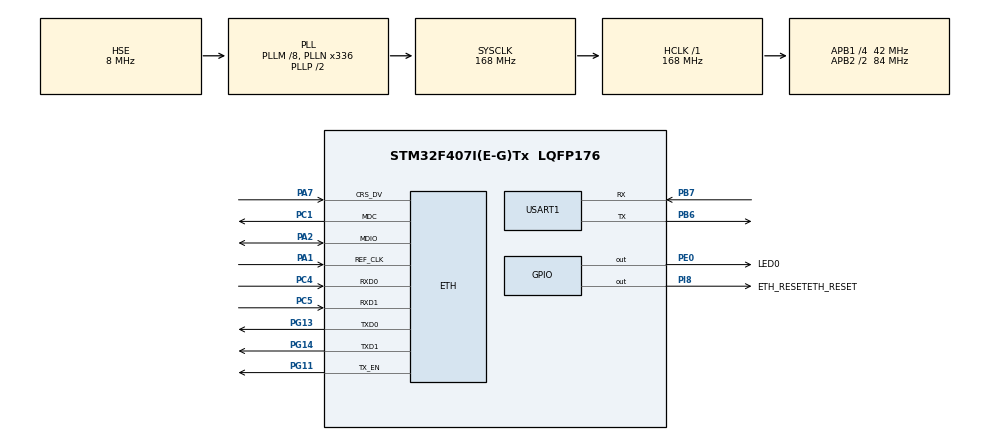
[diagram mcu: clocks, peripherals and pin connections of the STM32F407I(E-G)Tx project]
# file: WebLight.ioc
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ETH.MediaInterface=ETH_MEDIA_INTERFACE_RMII
ETH.PHY_DUPLEX_STATUS=0x2000
ETH.PHY_Name_RMII=userPHY
ETH.PHY_SPEED_STATUS=0x4010
ETH.PHY_SR=0x11
ETH.PhyAddress=0
FREERTOS.Tasks01=defaultTask,0,1024,StartDefaultTask,Default,NULL,Dynamic,NULL,NULL
LWIP.GATEWAY_ADDRESS=010.010.001.001
LWIP.IP_ADDRESS=010.010.001.022
LWIP.LWIP_DHCP=0
LWIP.LWIP_DNS=1
LWIP.LWIP_IGMP=1
LWIP.LWIP_MULTICAST_TX_OPTIONS=1
LWIP.NETMASK_ADDRESS=255.255.255.000
LWIP.Version=v2.0.3_Cube
Mcu.Family=STM32F4
Mcu.Name=STM32F407I(E-G)Tx
Mcu.Package=LQFP176
NVIC.ETH_IRQn=true\:5\:0\:true\:false\:true\:true\:true\:true
NVIC.PriorityGroup=NVIC_PRIORITYGROUP_4
NVIC.TIM1_UP_TIM10_IRQn=true\:0\:0\:false\:false\:true\:false\:false\:true
NVIC.TimeBase=TIM1_UP_TIM10_IRQn
NVIC.TimeBaseIP=TIM1
PA1.Mode=RMII
PA1.Signal=ETH_REF_CLK
PA13.Mode=Serial_Wire
PA13.Signal=SYS_JTMS-SWDIO
PA14.Mode=Serial_Wire
PA14.Signal=SYS_JTCK-SWCLK
PA2.Mode=RMII
PA2.Signal=ETH_MDIO
PA7.Mode=RMII
PA7.Signal=ETH_CRS_DV
PB6.Mode=Asynchronous
PB6.Signal=USART1_TX
PB7.Mode=Asynchronous
PB7.Signal=USART1_RX
PC1.Mode=RMII
PC1.Signal=ETH_MDC
PC4.Mode=RMII
PC4.Signal=ETH_RXD0
PC5.Mode=RMII
PC5.Signal=ETH_RXD1
PE0.GPIO_Label=LED0
PE0.GPIO_Speed=GPIO_SPEED_FREQ_HIGH
PE0.PinState=GPIO_PIN_SET
PE0.Signal=GPIO_Output
PG11.Mode=RMII
PG11.Signal=ETH_TX_EN
PG13.Mode=RMII
PG13.Signal=ETH_TXD0
PG14.Mode=RMII
PG14.Signal=ETH_TXD1
PH0-OSC_IN.Mode=HSE-External-Oscillator
PH0-OSC_IN.Signal=RCC_OSC_IN
PH1-OSC_OUT.Mode=HSE-External-Oscillator
PH1-OSC_OUT.Signal=RCC_OSC_OUT
PI8-\ ANTI\ TAMP2.GPIO_Label=ETH_RESETETH_RESET
PI8-\ ANTI\ TAMP2.GPIO_Speed=GPIO_SPEED_FREQ_VERY_HIGH
PI8-\ ANTI\ TAMP2.PinState=GPIO_PIN_SET
PI8-\ ANTI\ TAMP2.Signal=GPIO_Output
ProjectManager.HeapSize=0x200
ProjectManager.StackSize=0x400
ProjectManager.TargetToolchain=MDK-ARM V5
RCC.48MHZClocksFreq_Value=84000000
RCC.AHBFreq_Value=168000000
RCC.APB1CLKDivider=RCC_HCLK_DIV4
RCC.APB1Freq_Value=42000000
RCC.APB1TimFreq_Value=84000000
RCC.APB2CLKDivider=RCC_HCLK_DIV2
RCC.APB2Freq_Value=84000000
RCC.APB2TimFreq_Value=168000000
RCC.CortexFreq_Value=168000000
RCC.HCLKFreq_Value=168000000
RCC.HSE_VALUE=8000000
RCC.HSI_VALUE=16000000
RCC.LSE_VALUE=32768
RCC.PLLM=8
RCC.PLLN=336
RCC.PLLSourceVirtual=RCC_PLLSOURCE_HSE
RCC.SYSCLKFreq_VALUE=168000000
RCC.SYSCLKSource=RCC_SYSCLKSOURCE_PLLCLK
RCC.VCOOutputFreq_Value=336000000
USART1.VirtualMode=VM_ASYNC
VP_FREERTOS_VS_CMSIS_V1.Mode=CMSIS_V1
VP_LWIP_VS_Enabled.Mode=Enabled
VP_SYS_VS_tim1.Mode=TIM1
board=custom

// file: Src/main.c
/* USER CODE BEGIN Header */
/**
  ******************************************************************************
  * @file           : main.c
  * @brief          : Main program body
  ******************************************************************************
  * @attention
  *
  * <h2><center>&copy; Copyright (c) 2024 STMicroelectronics.
  * All rights reserved.</center></h2>
  *
  * This software component is licensed by ST under Ultimate Liberty license
  * SLA0044, the "License"; You may not use this file except in compliance with
  * the License. You may obtain a copy of the License at:
  *                             www.st.com/SLA0044
  *
  ******************************************************************************
  */
/* USER CODE END Header */

#include "main.h"
#include "cmsis_os.h"
#include "lwip.h"
#include "usart.h"
#include "gpio.h"

void SystemClock_Config(void);
void MX_FREERTOS_Init(void);

int main(void)
{

  /* MCU Configuration--------------------------------------------------------*/

  /* Reset of all peripherals, Initializes the Flash interface and the Systick. */
  HAL_Init();

  /* Configure the system clock */
  SystemClock_Config();

  /* Initialize all configured peripherals */
  MX_GPIO_Init();
  MX_USART1_UART_Init();
  /* USER CODE BEGIN 2 */
	//HAL_GPIO_WritePin(LED0_GPIO_Port, LED0_Pin, GPIO_PIN_RESET);
  /* USER CODE END 2 */

  /* Call init function for freertos objects (in freertos.c) */
  MX_FREERTOS_Init();

  /* Start scheduler */
  osKernelStart();

  /* We should never get here as control is now taken by the scheduler */

  /* Infinite loop */
  while (1)
  {

  }
}

void SystemClock_Config(void)
{
  RCC_OscInitTypeDef RCC_OscInitStruct = {0};
  RCC_ClkInitTypeDef RCC_ClkInitStruct = {0};

  /** Configure the main internal regulator output voltage
  */
  __HAL_RCC_PWR_CLK_ENABLE();
  __HAL_PWR_VOLTAGESCALING_CONFIG(PWR_REGULATOR_VOLTAGE_SCALE1);
  /** Initializes the CPU, AHB and APB busses clocks
  */
  RCC_OscInitStruct.OscillatorType = RCC_OSCILLATORTYPE_HSE;
  RCC_OscInitStruct.HSEState = RCC_HSE_ON;
  RCC_OscInitStruct.PLL.PLLState = RCC_PLL_ON;
  RCC_OscInitStruct.PLL.PLLSource = RCC_PLLSOURCE_HSE;
  RCC_OscInitStruct.PLL.PLLM = 8;
  RCC_OscInitStruct.PLL.PLLN = 336;
  RCC_OscInitStruct.PLL.PLLP = RCC_PLLP_DIV2;
  RCC_OscInitStruct.PLL.PLLQ = 4;
  if (HAL_RCC_OscConfig(&RCC_OscInitStruct) != HAL_OK)
  {
    Error_Handler();
  }
  /** Initializes the CPU, AHB and APB busses clocks
  */
  RCC_ClkInitStruct.ClockType = RCC_CLOCKTYPE_HCLK|RCC_CLOCKTYPE_SYSCLK
                              |RCC_CLOCKTYPE_PCLK1|RCC_CLOCKTYPE_PCLK2;
  RCC_ClkInitStruct.SYSCLKSource = RCC_SYSCLKSOURCE_PLLCLK;
  RCC_ClkInitStruct.AHBCLKDivider = RCC_SYSCLK_DIV1;
  RCC_ClkInitStruct.APB1CLKDivider = RCC_HCLK_DIV4;
  RCC_ClkInitStruct.APB2CLKDivider = RCC_HCLK_DIV2;

  if (HAL_RCC_ClockConfig(&RCC_ClkInitStruct, FLASH_LATENCY_5) != HAL_OK)
  {
    Error_Handler();
  }
}

void HAL_TIM_PeriodElapsedCallback(TIM_HandleTypeDef *htim)
{
  if (htim->Instance == TIM1) {
    HAL_IncTick();
  }
}

void Error_Handler(void)
{
}

/************************ (C) COPYRIGHT STMicroelectronics *****END OF FILE****/

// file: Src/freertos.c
/* USER CODE BEGIN Header */
/**
  ******************************************************************************
  * File Name          : freertos.c
  * Description        : Code for freertos applications
  ******************************************************************************
  * @attention
  *
  * <h2><center>&copy; Copyright (c) 2024 STMicroelectronics.
  * All rights reserved.</center></h2>
  *
  * This software component is licensed by ST under Ultimate Liberty license
  * SLA0044, the "License"; You may not use this file except in compliance with
  * the License. You may obtain a copy of the License at:
  *                             www.st.com/SLA0044
  *
  ******************************************************************************
  */
/* USER CODE END Header */

#include "FreeRTOS.h"
#include "task.h"
#include "main.h"
#include "cmsis_os.h"

/* USER CODE BEGIN Includes */
#include "usart.h"
#include "http_server.h"
/* USER CODE END Includes */

osThreadId defaultTaskHandle;

void StartDefaultTask(void const * argument);

extern void MX_LWIP_Init(void);
void MX_FREERTOS_Init(void); /* (MISRA C 2004 rule 8.1) */

/* GetIdleTaskMemory prototype (linked to static allocation support) */
void vApplicationGetIdleTaskMemory( StaticTask_t **ppxIdleTaskTCBBuffer, StackType_t **ppxIdleTaskStackBuffer, uint32_t *pulIdleTaskStackSize );

/* USER CODE BEGIN GET_IDLE_TASK_MEMORY */
static StaticTask_t xIdleTaskTCBBuffer;
static StackType_t xIdleStack[configMINIMAL_STACK_SIZE];

void vApplicationGetIdleTaskMemory( StaticTask_t **ppxIdleTaskTCBBuffer, StackType_t **ppxIdleTaskStackBuffer, uint32_t *pulIdleTaskStackSize )
{
  *ppxIdleTaskTCBBuffer = &xIdleTaskTCBBuffer;
  *ppxIdleTaskStackBuffer = &xIdleStack[0];
  *pulIdleTaskStackSize = configMINIMAL_STACK_SIZE;
  /* place for user code */
}
/* USER CODE END GET_IDLE_TASK_MEMORY */

void MX_FREERTOS_Init(void) {

  /* Create the thread(s) */
  /* definition and creation of defaultTask */
  osThreadDef(defaultTask, StartDefaultTask, osPriorityNormal, 0, 1024);
  defaultTaskHandle = osThreadCreate(osThread(defaultTask), NULL);

}

void StartDefaultTask(void const * argument)
{

  /* init code for LWIP */
  MX_LWIP_Init();

  /* USER CODE BEGIN StartDefaultTask */
  /* Infinite loop */
	printf("LWIP init down!\n");
  for(;;)
  {
		vHttpServerTask();
    osDelay(1);
  }
  /* USER CODE END StartDefaultTask */
}

/************************ (C) COPYRIGHT STMicroelectronics *****END OF FILE****/
